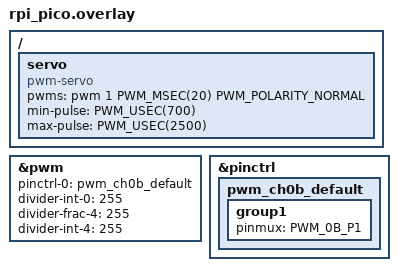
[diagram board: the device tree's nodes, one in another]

#include </home/tatiana/zephyrproject/zephyr/include/zephyr/dt-bindings/pinctrl/rpi-pico-rp2040-pinctrl.h>


/ {
	servo: servo {
		compatible = "pwm-servo";
		pwms = <&pwm 1 PWM_MSEC(20) PWM_POLARITY_NORMAL>;
		min-pulse = <PWM_USEC(700)>;
		max-pulse = <PWM_USEC(2500)>;
	};
	
	
};


&pwm {
	pinctrl-0 = <&pwm_ch0b_default>;
	pinctrl-names = "default";
	divider-int-0 = <255>;
	status = "okay";
	divider-frac-4 = <255>;
	divider-int-4 = <255>;
};
&pinctrl {
	pwm_ch0b_default: pwm_ch0b_default {
		group1 {
			pinmux = <PWM_0B_P1>;
		};
	};
};
